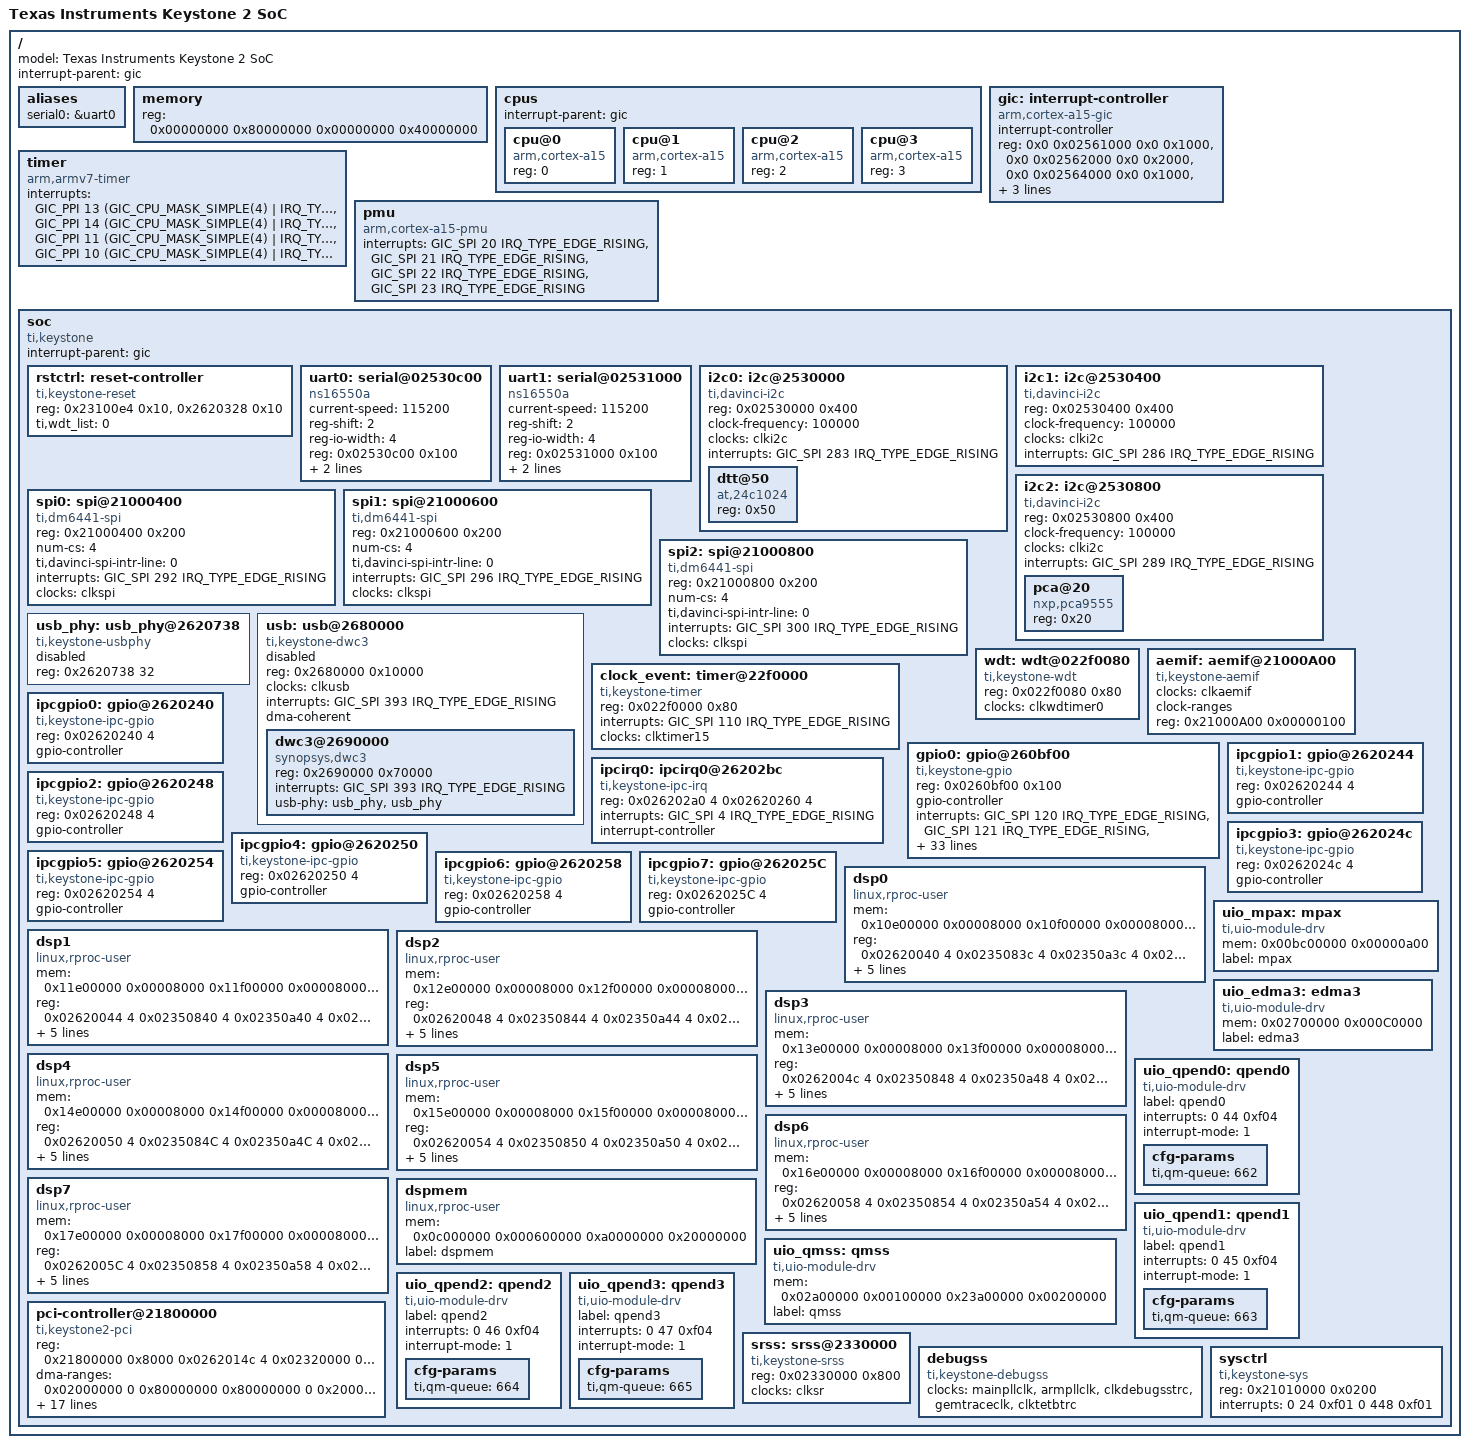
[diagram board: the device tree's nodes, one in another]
/*
 * Copyright 2013 Texas Instruments, Inc.
 *
 * This program is free software; you can redistribute it and/or modify
 * it under the terms of the GNU General Public License version 2 as
 * published by the Free Software Foundation.
 */

#include <dt-bindings/interrupt-controller/arm-gic.h>
#include <dt-bindings/gpio/gpio.h>

#include "skeleton.dtsi"

/ {
	model = "Texas Instruments Keystone 2 SoC";
	#address-cells = <2>;
	#size-cells = <2>;
	interrupt-parent = <&gic>;

	aliases {
		serial0	= &uart0;
	};

	memory {
		reg = <0x00000000 0x80000000 0x00000000 0x40000000>;
	};

	cpus {
		#address-cells = <1>;
		#size-cells = <0>;

		interrupt-parent = <&gic>;

		cpu@0 {
			compatible = "arm,cortex-a15";
			device_type = "cpu";
			reg = <0>;
		};

		cpu@1 {
			compatible = "arm,cortex-a15";
			device_type = "cpu";
			reg = <1>;
		};

		cpu@2 {
			compatible = "arm,cortex-a15";
			device_type = "cpu";
			reg = <2>;
		};

		cpu@3 {
			compatible = "arm,cortex-a15";
			device_type = "cpu";
			reg = <3>;
		};
	};

	gic: interrupt-controller {
		compatible = "arm,cortex-a15-gic";
		#interrupt-cells = <3>;
		#size-cells = <0>;
		#address-cells = <1>;
		interrupt-controller;
		reg = <0x0 0x02561000 0x0 0x1000>,
		      <0x0 0x02562000 0x0 0x2000>,
		      <0x0 0x02564000 0x0 0x1000>,
		      <0x0 0x02566000 0x0 0x2000>;
		interrupts = <GIC_PPI 9 (GIC_CPU_MASK_SIMPLE(4) |
				IRQ_TYPE_LEVEL_HIGH)>;
	};

	timer {
		compatible = "arm,armv7-timer";
		interrupts =
			<GIC_PPI 13
				(GIC_CPU_MASK_SIMPLE(4) | IRQ_TYPE_LEVEL_LOW)>,
			<GIC_PPI 14
				(GIC_CPU_MASK_SIMPLE(4) | IRQ_TYPE_LEVEL_LOW)>,
			<GIC_PPI 11
				(GIC_CPU_MASK_SIMPLE(4) | IRQ_TYPE_LEVEL_LOW)>,
			<GIC_PPI 10
				(GIC_CPU_MASK_SIMPLE(4) | IRQ_TYPE_LEVEL_LOW)>;
	};

	pmu {
		compatible = "arm,cortex-a15-pmu";
		interrupts = <GIC_SPI 20 IRQ_TYPE_EDGE_RISING>,
			     <GIC_SPI 21 IRQ_TYPE_EDGE_RISING>,
			     <GIC_SPI 22 IRQ_TYPE_EDGE_RISING>,
			     <GIC_SPI 23 IRQ_TYPE_EDGE_RISING>;
	};

	soc {
		#address-cells = <1>;
		#size-cells = <1>;
		compatible = "ti,keystone","simple-bus";
		interrupt-parent = <&gic>;
		ranges = <0x0 0x0 0x0 0xc0000000>;

		rstctrl: reset-controller {
			compatible = "ti,keystone-reset";
			reg = <0x23100e4 0x10>, <0x2620328 0x10>;
			reg-names = "pllregs", "muxregs";
			ti,wdt_list = <0>;
		};

		/include/ "keystone-clocks.dtsi"

		uart0: serial@02530c00 {
			compatible = "ns16550a";
			current-speed = <115200>;
			reg-shift = <2>;
			reg-io-width = <4>;
			reg = <0x02530c00 0x100>;
			clocks	= <&clkuart0>;
			interrupts = <GIC_SPI 277 IRQ_TYPE_EDGE_RISING>;
		};

		uart1:	serial@02531000 {
			compatible = "ns16550a";
			current-speed = <115200>;
			reg-shift = <2>;
			reg-io-width = <4>;
			reg = <0x02531000 0x100>;
			clocks	= <&clkuart1>;
			interrupts = <GIC_SPI 280 IRQ_TYPE_EDGE_RISING>;
		};

		i2c0: i2c@2530000 {
			compatible = "ti,davinci-i2c";
			reg = <0x02530000 0x400>;
			clock-frequency = <100000>;
			clocks = <&clki2c>;
			interrupts = <GIC_SPI 283 IRQ_TYPE_EDGE_RISING>;
			#address-cells = <1>;
			#size-cells = <0>;

			dtt@50 {
				compatible = "at,24c1024";
				reg = <0x50>;
			};
		};

		i2c1: i2c@2530400 {
			compatible = "ti,davinci-i2c";
			reg = <0x02530400 0x400>;
			clock-frequency = <100000>;
			clocks = <&clki2c>;
			interrupts = <GIC_SPI 286 IRQ_TYPE_EDGE_RISING>;
		};

		i2c2: i2c@2530800 {
			compatible = "ti,davinci-i2c";
			reg = <0x02530800 0x400>;
			clock-frequency = <100000>;
			clocks = <&clki2c>;
			interrupts = <GIC_SPI 289 IRQ_TYPE_EDGE_RISING>;
			#address-cells = <1>;
			#size-cells = <0>;

			pca@20 {
				compatible = "nxp,pca9555";
				reg = <0x20>;
			};
		};

		spi0: spi@21000400 {
			compatible = "ti,dm6441-spi";
			reg = <0x21000400 0x200>;
			num-cs = <4>;
			ti,davinci-spi-intr-line = <0>;
			interrupts = <GIC_SPI 292 IRQ_TYPE_EDGE_RISING>;
			clocks = <&clkspi>;
		};

		spi1: spi@21000600 {
			compatible = "ti,dm6441-spi";
			reg = <0x21000600 0x200>;
			num-cs = <4>;
			ti,davinci-spi-intr-line = <0>;
			interrupts = <GIC_SPI 296 IRQ_TYPE_EDGE_RISING>;
			clocks = <&clkspi>;
		};

		spi2: spi@21000800 {
			compatible = "ti,dm6441-spi";
			reg = <0x21000800 0x200>;
			num-cs = <4>;
			ti,davinci-spi-intr-line = <0>;
			interrupts = <GIC_SPI 300 IRQ_TYPE_EDGE_RISING>;
			clocks = <&clkspi>;
		};

		usb_phy: usb_phy@2620738 {
			compatible = "ti,keystone-usbphy";
			#address-cells = <1>;
			#size-cells = <1>;
			reg = <0x2620738 32>;
			status = "disabled";
		};

		usb: usb@2680000 {
			compatible = "ti,keystone-dwc3";
			#address-cells = <1>;
			#size-cells = <1>;
			reg = <0x2680000 0x10000>;
			clocks = <&clkusb>;
			clock-names = "usb";
			interrupts = <GIC_SPI 393 IRQ_TYPE_EDGE_RISING>;
			ranges;
			status = "disabled";
			dma-coherent;

			dwc3@2690000 {
				compatible = "synopsys,dwc3";
				reg = <0x2690000 0x70000>;
				interrupts = <GIC_SPI 393 IRQ_TYPE_EDGE_RISING>;
				usb-phy = <&usb_phy>, <&usb_phy>;
			};
		};

		wdt: wdt@022f0080 {
			compatible = "ti,keystone-wdt","ti,davinci-wdt";
			reg = <0x022f0080 0x80>;
			clocks = <&clkwdtimer0>;
		};

		clock_event: timer@22f0000 {
			compatible = "ti,keystone-timer";
			reg = <0x022f0000 0x80>;
			interrupts = <GIC_SPI 110 IRQ_TYPE_EDGE_RISING>;
			clocks = <&clktimer15>;
		};

		aemif: aemif@21000A00 {
			compatible = "ti,keystone-aemif", "ti,davinci-aemif";
			#address-cells = <2>;
			#size-cells = <1>;
			clocks = <&clkaemif>;
			clock-names = "aemif";
			clock-ranges;

			reg = <0x21000A00 0x00000100>;
			ranges = <0 0 0x30000000 0x10000000
				  1 0 0x21000A00 0x00000100>;
		};

		gpio0: gpio@260bf00 {
			compatible = "ti,keystone-gpio";
			reg = <0x0260bf00 0x100>;
			gpio-controller;
			#gpio-cells = <2>;
			/* HW Interrupts mapped to GPIO pins */
			interrupts = <GIC_SPI 120 IRQ_TYPE_EDGE_RISING>,
					<GIC_SPI 121 IRQ_TYPE_EDGE_RISING>,
					<GIC_SPI 122 IRQ_TYPE_EDGE_RISING>,
					<GIC_SPI 123 IRQ_TYPE_EDGE_RISING>,
					<GIC_SPI 124 IRQ_TYPE_EDGE_RISING>,
					<GIC_SPI 125 IRQ_TYPE_EDGE_RISING>,
					<GIC_SPI 126 IRQ_TYPE_EDGE_RISING>,
					<GIC_SPI 127 IRQ_TYPE_EDGE_RISING>,
					<GIC_SPI 128 IRQ_TYPE_EDGE_RISING>,
					<GIC_SPI 129 IRQ_TYPE_EDGE_RISING>,
					<GIC_SPI 130 IRQ_TYPE_EDGE_RISING>,
					<GIC_SPI 131 IRQ_TYPE_EDGE_RISING>,
					<GIC_SPI 132 IRQ_TYPE_EDGE_RISING>,
					<GIC_SPI 133 IRQ_TYPE_EDGE_RISING>,
					<GIC_SPI 134 IRQ_TYPE_EDGE_RISING>,
					<GIC_SPI 135 IRQ_TYPE_EDGE_RISING>,
					<GIC_SPI 136 IRQ_TYPE_EDGE_RISING>,
					<GIC_SPI 137 IRQ_TYPE_EDGE_RISING>,
					<GIC_SPI 138 IRQ_TYPE_EDGE_RISING>,
					<GIC_SPI 139 IRQ_TYPE_EDGE_RISING>,
					<GIC_SPI 140 IRQ_TYPE_EDGE_RISING>,
					<GIC_SPI 141 IRQ_TYPE_EDGE_RISING>,
					<GIC_SPI 142 IRQ_TYPE_EDGE_RISING>,
					<GIC_SPI 143 IRQ_TYPE_EDGE_RISING>,
					<GIC_SPI 144 IRQ_TYPE_EDGE_RISING>,
					<GIC_SPI 145 IRQ_TYPE_EDGE_RISING>,
					<GIC_SPI 146 IRQ_TYPE_EDGE_RISING>,
					<GIC_SPI 147 IRQ_TYPE_EDGE_RISING>,
					<GIC_SPI 148 IRQ_TYPE_EDGE_RISING>,
					<GIC_SPI 149 IRQ_TYPE_EDGE_RISING>,
					<GIC_SPI 150 IRQ_TYPE_EDGE_RISING>,
					<GIC_SPI 151 IRQ_TYPE_EDGE_RISING>;
			clocks = <&clkgpio>;
			clock-names = "gpio";
			ti,ngpio = <32>;
			ti,davinci-gpio-unbanked = <32>;
		};

		ipcirq0: ipcirq0@26202bc {	/* ipc irq chip */
			compatible = "ti,keystone-ipc-irq";
			reg  = <0x026202a0 4	/* host ack register */
			        0x02620260 4>;	/* ipc host interrupt generation register */
			interrupts = <GIC_SPI 4 IRQ_TYPE_EDGE_RISING>;/* it should match the value in irqs.h */
						 /* following is the source id to irq mapping
						   SRCS0 <-> ipc hw irq 0 ... SRCS27 <-> ipc hw irq 27
						   note that SRCS0 is bit 4 in ipc register */
			interrupt-controller;
			#interrupt-cells = <2>;
		};

		ipcgpio0: gpio@2620240 {
			compatible = "ti,keystone-ipc-gpio";
			reg = <0x02620240 4>;
			gpio-controller;
			#gpio-cells = <2>;
		};

		ipcgpio1: gpio@2620244 {
			compatible = "ti,keystone-ipc-gpio";
			reg = <0x02620244 4>;
			gpio-controller;
			#gpio-cells = <2>;
		};

		ipcgpio2: gpio@2620248 {
			compatible = "ti,keystone-ipc-gpio";
			reg = <0x02620248 4>;
			gpio-controller;
			#gpio-cells = <2>;
		};

		ipcgpio3: gpio@262024c {
			compatible = "ti,keystone-ipc-gpio";
			reg = <0x0262024c 4>;
			gpio-controller;
			#gpio-cells = <2>;
		};

		ipcgpio4: gpio@2620250 {
			compatible = "ti,keystone-ipc-gpio";
			reg = <0x02620250 4>;
			gpio-controller;
			#gpio-cells = <2>;
		};

		ipcgpio5: gpio@2620254 {
			compatible = "ti,keystone-ipc-gpio";
			reg = <0x02620254 4>;
			gpio-controller;
			#gpio-cells = <2>;
		};

		ipcgpio6: gpio@2620258 {
			compatible = "ti,keystone-ipc-gpio";
			reg = <0x02620258 4>;
			gpio-controller;
			#gpio-cells = <2>;
		};

		ipcgpio7: gpio@262025C {
			compatible = "ti,keystone-ipc-gpio";
			reg = <0x0262025C 4>;
			gpio-controller;
			#gpio-cells = <2>;
		};

		dsp0: dsp0 {
			compatible = "linux,rproc-user";
			mem = <0x10e00000 0x00008000
			       0x10f00000 0x00008000
			       0x10800000 0x00100000>;
			reg = <0x02620040 4
			       0x0235083c 4
			       0x02350a3c 4
			       0x02620240 4>;
			reg-names = "boot-address", "psc-mdstat", "psc-mdctl", "ipcgr";
			interrupt-parent = <&ipcirq0>;
			interrupts = <8 0 0 0>;
			kick-gpio = <&ipcgpio0 27 0>;
			clocks = <&clkgem0>;
			label = "dsp0";
		};

		dsp1: dsp1 {
			compatible = "linux,rproc-user";
			mem = <0x11e00000 0x00008000
			       0x11f00000 0x00008000
			       0x11800000 0x00100000>;
			reg = <0x02620044 4
			       0x02350840 4
			       0x02350a40 4
			       0x02620244 4>;
			reg-names = "boot-address", "psc-mdstat", "psc-mdctl", "ipcgr";
			interrupt-parent = <&ipcirq0>;
			interrupts = <9 0 1 0>;
			kick-gpio = <&ipcgpio1 27 0>;
			clocks = <&clkgem1>;
			label = "dsp1";
		};

		dsp2: dsp2 {
			compatible = "linux,rproc-user";
			mem = <0x12e00000 0x00008000
			       0x12f00000 0x00008000
			       0x12800000 0x00100000>;
			reg = <0x02620048 4
			       0x02350844 4
			       0x02350a44 4
			       0x02620248 4>;
			reg-names = "boot-address", "psc-mdstat", "psc-mdctl", "ipcgr";
			interrupt-parent = <&ipcirq0>;
			interrupts = <10 0 2 0>;
			kick-gpio = <&ipcgpio2 27 0>;
			clocks = <&clkgem2>;
			label = "dsp2";
		};

		dsp3: dsp3 {
			compatible = "linux,rproc-user";
			mem = <0x13e00000 0x00008000
			       0x13f00000 0x00008000
			       0x13800000 0x00100000>;
			reg = <0x0262004c 4
			       0x02350848 4
			       0x02350a48 4
			       0x0262024c 4>;
			reg-names = "boot-address", "psc-mdstat", "psc-mdctl", "ipcgr";
			interrupt-parent = <&ipcirq0>;
			interrupts = <11 0 3 0>;
			kick-gpio = <&ipcgpio3 27 0>;
			clocks = <&clkgem3>;
			label = "dsp3";
		};

		dsp4: dsp4 {
			compatible = "linux,rproc-user";
			mem = <0x14e00000 0x00008000
			       0x14f00000 0x00008000
			       0x14800000 0x00100000>;
			reg = <0x02620050 4
			       0x0235084C 4
			       0x02350a4C 4
			       0x02620250 4>;
			reg-names = "boot-address", "psc-mdstat", "psc-mdctl", "ipcgr";
			interrupt-parent = <&ipcirq0>;
			interrupts = <12 0 4 0>;
			kick-gpio = <&ipcgpio4 27 0>;
			clocks = <&clkgem4>;
			label = "dsp4";
		};

		dsp5: dsp5 {
			compatible = "linux,rproc-user";
			mem = <0x15e00000 0x00008000
			       0x15f00000 0x00008000
			       0x15800000 0x00100000>;
			reg = <0x02620054 4
			       0x02350850 4
			       0x02350a50 4
			       0x02620254 4>;
			reg-names = "boot-address", "psc-mdstat", "psc-mdctl", "ipcgr";
			interrupt-parent = <&ipcirq0>;
			interrupts = <13 0 5 0>;
			kick-gpio = <&ipcgpio5 27 0>;
			clocks = <&clkgem5>;
			label = "dsp5";
		};

		dsp6: dsp6 {
			compatible = "linux,rproc-user";
			mem = <0x16e00000 0x00008000
			       0x16f00000 0x00008000
			       0x16800000 0x00100000>;
			reg = <0x02620058 4
			       0x02350854 4
			       0x02350a54 4
			       0x02620258 4>;
			reg-names = "boot-address", "psc-mdstat", "psc-mdctl", "ipcgr";
			interrupt-parent = <&ipcirq0>;
			interrupts = <14 0 6 0>;
			kick-gpio = <&ipcgpio6 27 0>;
			clocks = <&clkgem6>;
			label = "dsp6";
		};

		dsp7: dsp7 {
			compatible = "linux,rproc-user";
			mem = <0x17e00000 0x00008000
			       0x17f00000 0x00008000
			       0x17800000 0x00100000>;
			reg = <0x0262005C 4
			       0x02350858 4
			       0x02350a58 4
			       0x0262025C 4>;
			reg-names = "boot-address", "psc-mdstat", "psc-mdctl", "ipcgr";
			interrupt-parent = <&ipcirq0>;
			interrupts = <15 0 7 0>;
			kick-gpio = <&ipcgpio7 27 0>;
			clocks = <&clkgem7>;
			label = "dsp7";
		};

		dspmem: dspmem {
			compatible = "linux,rproc-user";
			mem  = <0x0c000000 0x000600000
					0xa0000000 0x20000000>;
			label = "dspmem";
		};
		uio_mpax: mpax {
			compatible = "ti,uio-module-drv";
			mem  = <0x00bc00000 0x00000a00>;
			label = "mpax";
		};

		uio_edma3: edma3 {
			compatible = "ti,uio-module-drv";
			mem = <0x02700000 0x000C0000>;
			label = "edma3";
		};

		uio_qmss: qmss {
			compatible = "ti,uio-module-drv";
			mem  = <0x02a00000 0x00100000
				0x23a00000 0x00200000>;
			label = "qmss";
		};

		uio_qpend0: qpend0 {
			compatible = "ti,uio-module-drv";
			label = "qpend0";
			interrupts = <0 44 0xf04>;
			interrupt-mode = <1>; /* Interrupt mode oneshot */
			cfg-params
			{
				ti,qm-queue = <662>;
			};
		};

		uio_qpend1: qpend1 {
			compatible = "ti,uio-module-drv";
			label = "qpend1";
			interrupts = <0 45 0xf04>;
			interrupt-mode = <1>; /* Interrupt mode oneshot */
			cfg-params
			{
				ti,qm-queue = <663>;
			};
		};

		uio_qpend2: qpend2 {
			compatible = "ti,uio-module-drv";
			label = "qpend2";
			interrupts = <0 46 0xf04>;
			interrupt-mode = <1>; /* Interrupt mode oneshot */
			cfg-params
			{
				ti,qm-queue = <664>;
			};
		};

		uio_qpend3: qpend3 {
			compatible = "ti,uio-module-drv";
			label = "qpend3";
			interrupts = <0 47 0xf04>;
			interrupt-mode = <1>; /* Interrupt mode oneshot */
			cfg-params
			{
				ti,qm-queue = <665>;
			};
		};

		pci-controller@21800000 {
			device_type = "pci";
			#address-cells = <3>;
			#size-cells = <2>;
			#interrupt-cells = <2>;
			compatible = "ti,keystone2-pci";
			reg =  <0x21800000 0x8000	/* pcie-regs */
				0x0262014c 4		/* device cfg */
				0x02320000 0x4000>;	/* Keystone2 serdes cfg */

			/* outbound pci resources */
			ranges = <0x02000000 0 0x50000000 0x50000000 0 0x10000000
				  0x01000000 0 0 0x24000000 0 0x4000>;

			/* inbound dma range */
			dma-ranges = <0x02000000 0 0x80000000 0x80000000 0 0x20000000>;

			interrupt-parent = <&gic>;
			interrupts = <GIC_SPI 26 (GIC_CPU_MASK_SIMPLE(4) | IRQ_TYPE_EDGE_RISING)>,
					<GIC_SPI 27 (GIC_CPU_MASK_SIMPLE(4) | IRQ_TYPE_EDGE_RISING)>,
					<GIC_SPI 28 (GIC_CPU_MASK_SIMPLE(4) | IRQ_TYPE_EDGE_RISING)>,
					<GIC_SPI 29 (GIC_CPU_MASK_SIMPLE(4) | IRQ_TYPE_EDGE_RISING)>, /* 4 Legacy IRQs */
					<GIC_SPI 30 (GIC_CPU_MASK_SIMPLE(4) | IRQ_TYPE_EDGE_RISING)>,
					<GIC_SPI 31 (GIC_CPU_MASK_SIMPLE(4) | IRQ_TYPE_EDGE_RISING)>,
					<GIC_SPI 32 (GIC_CPU_MASK_SIMPLE(4) | IRQ_TYPE_EDGE_RISING)>,
					<GIC_SPI 33 (GIC_CPU_MASK_SIMPLE(4) | IRQ_TYPE_EDGE_RISING)>,
					<GIC_SPI 34 (GIC_CPU_MASK_SIMPLE(4) | IRQ_TYPE_EDGE_RISING)>,
					<GIC_SPI 35 (GIC_CPU_MASK_SIMPLE(4) | IRQ_TYPE_EDGE_RISING)>,
					<GIC_SPI 36 (GIC_CPU_MASK_SIMPLE(4) | IRQ_TYPE_EDGE_RISING)>,
					<GIC_SPI 37 (GIC_CPU_MASK_SIMPLE(4) | IRQ_TYPE_EDGE_RISING)>, /* 8 MSI IRQs */
					<GIC_SPI 38 (GIC_CPU_MASK_SIMPLE(4) | IRQ_TYPE_EDGE_RISING)>; /* Error IRQ */
			clocks = <&clkpcie>;
			clock-names = "pcie";
			enable-linktrain; /* When the boot loader enables link train and configure ep
					   * remove this attribute */
		};

                srss: srss@2330000 {
                        compatible = "ti,keystone-srss";
                        reg = <0x02330000 0x800>;
                        clocks = <&clksr>;
                        clock-names = "srssclock";
                };

                debugss: debugss {
                        compatible = "ti,keystone-debugss";
                        clocks = <&mainpllclk>, <&armpllclk>, <&clkdebugsstrc>, <&gemtraceclk>, <&clktetbtrc>;
                        clock-names = "mainpllclock", "armpllclock", "debugssclock", "gemtraceclock", "tetbclock";
                };

		sysctrl {
			/* add all system level resources here that are used by keystone soc code */
			compatible = "ti,keystone-sys";
			reg = <0x21010000 0x0200>; /* DDR3 controller reg */
			interrupts = <0 24 0xf01    /* L1L2 ECC error interrupt */
				      0 448 0xf01>; /* DDR3 ECC error interrupt */
		};
	};
};
